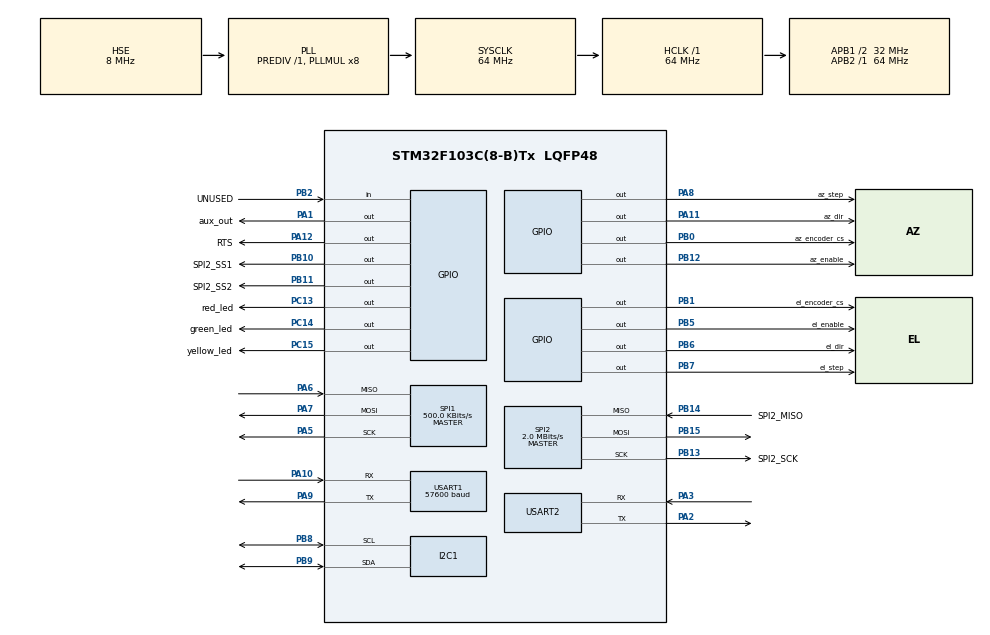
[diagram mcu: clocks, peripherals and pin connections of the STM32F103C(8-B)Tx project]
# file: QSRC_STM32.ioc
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Dma.Request0=USART2_RX
Dma.Request1=USART2_TX
Dma.Request2=USART1_RX
Dma.Request3=USART1_TX
Dma.USART1_RX.2.Direction=DMA_PERIPH_TO_MEMORY
Dma.USART1_RX.2.Instance=DMA1_Channel5
Dma.USART1_RX.2.MemDataAlignment=DMA_MDATAALIGN_BYTE
Dma.USART1_RX.2.MemInc=DMA_MINC_ENABLE
Dma.USART1_RX.2.Mode=DMA_NORMAL
Dma.USART1_RX.2.PeriphDataAlignment=DMA_PDATAALIGN_BYTE
Dma.USART1_RX.2.PeriphInc=DMA_PINC_DISABLE
Dma.USART1_RX.2.Priority=DMA_PRIORITY_MEDIUM
Dma.USART1_TX.3.Direction=DMA_MEMORY_TO_PERIPH
Dma.USART1_TX.3.Instance=DMA1_Channel4
Dma.USART1_TX.3.MemDataAlignment=DMA_MDATAALIGN_BYTE
Dma.USART1_TX.3.MemInc=DMA_MINC_ENABLE
Dma.USART1_TX.3.Mode=DMA_NORMAL
Dma.USART1_TX.3.PeriphDataAlignment=DMA_PDATAALIGN_BYTE
Dma.USART1_TX.3.PeriphInc=DMA_PINC_DISABLE
Dma.USART1_TX.3.Priority=DMA_PRIORITY_MEDIUM
Dma.USART2_RX.0.Direction=DMA_PERIPH_TO_MEMORY
Dma.USART2_RX.0.Instance=DMA1_Channel6
Dma.USART2_RX.0.MemDataAlignment=DMA_MDATAALIGN_BYTE
Dma.USART2_RX.0.MemInc=DMA_MINC_ENABLE
Dma.USART2_RX.0.Mode=DMA_NORMAL
Dma.USART2_RX.0.PeriphDataAlignment=DMA_PDATAALIGN_BYTE
Dma.USART2_RX.0.PeriphInc=DMA_PINC_DISABLE
Dma.USART2_RX.0.Priority=DMA_PRIORITY_LOW
Dma.USART2_TX.1.Direction=DMA_MEMORY_TO_PERIPH
Dma.USART2_TX.1.Instance=DMA1_Channel7
Dma.USART2_TX.1.MemDataAlignment=DMA_MDATAALIGN_BYTE
Dma.USART2_TX.1.MemInc=DMA_MINC_ENABLE
Dma.USART2_TX.1.Mode=DMA_NORMAL
Dma.USART2_TX.1.PeriphDataAlignment=DMA_PDATAALIGN_BYTE
Dma.USART2_TX.1.PeriphInc=DMA_PINC_DISABLE
Dma.USART2_TX.1.Priority=DMA_PRIORITY_LOW
Mcu.Family=STM32F1
Mcu.Name=STM32F103C(8-B)Tx
Mcu.Package=LQFP48
NVIC.DMA1_Channel4_IRQn=true\:0\:0\:false\:false\:true\:true\:true
NVIC.DMA1_Channel5_IRQn=true\:0\:0\:false\:false\:true\:true\:true
NVIC.DMA1_Channel6_IRQn=true\:0\:0\:false\:false\:true\:true\:true
NVIC.DMA1_Channel7_IRQn=true\:0\:0\:false\:false\:true\:true\:true
NVIC.I2C1_ER_IRQn=true\:0\:0\:false\:false\:true\:true\:true
NVIC.I2C1_EV_IRQn=true\:0\:0\:false\:false\:true\:true\:true
NVIC.PriorityGroup=NVIC_PRIORITYGROUP_4
NVIC.SPI1_IRQn=true\:0\:0\:false\:false\:true\:true\:true
NVIC.TIM2_IRQn=true\:7\:0\:true\:false\:true\:true\:true
NVIC.TIM3_IRQn=true\:7\:0\:true\:false\:true\:true\:true
NVIC.TIM4_IRQn=true\:0\:0\:false\:false\:true\:true\:true
NVIC.USART1_IRQn=true\:0\:0\:false\:false\:true\:true\:true
NVIC.USART2_IRQn=true\:0\:0\:false\:false\:true\:true\:true
PA1.GPIO_Label=aux_out
PA1.Signal=GPIO_Output
PA10.GPIO_PuPd=GPIO_PULLUP
PA10.Mode=Asynchronous
PA10.Signal=USART1_RX
PA11.GPIO_Label=az_dir
PA11.Signal=GPIO_Output
PA12.GPIO_Label=RTS
PA12.GPIO_Speed=GPIO_SPEED_FREQ_HIGH
PA12.Signal=GPIO_Output
PA13.Mode=JTAG_5_pins
PA13.Signal=SYS_JTMS-SWDIO
PA14.Mode=JTAG_5_pins
PA14.Signal=SYS_JTCK-SWCLK
PA15.Mode=JTAG_5_pins
PA15.Signal=SYS_JTDI
PA2.Mode=Asynchronous
PA2.Signal=USART2_TX
PA3.Mode=Asynchronous
PA3.Signal=USART2_RX
PA5.Mode=Full_Duplex_Master
PA5.Signal=SPI1_SCK
PA6.Mode=Full_Duplex_Master
PA6.Signal=SPI1_MISO
PA7.Mode=Full_Duplex_Master
PA7.Signal=SPI1_MOSI
PA8.GPIO_Label=az_step
PA8.Signal=GPIO_Output
PA9.Mode=Asynchronous
PA9.Signal=USART1_TX
PB0.GPIO_Label=az_encoder_cs
PB0.GPIO_Speed=GPIO_SPEED_FREQ_HIGH
PB0.PinState=GPIO_PIN_SET
PB0.Signal=GPIO_Output
PB1.GPIO_Label=el_encoder_cs
PB1.GPIO_Speed=GPIO_SPEED_FREQ_HIGH
PB1.PinState=GPIO_PIN_SET
PB1.Signal=GPIO_Output
PB10.GPIO_Label=SPI2_SS1
PB10.Signal=GPIO_Output
PB11.GPIO_Label=SPI2_SS2
PB11.Signal=GPIO_Output
PB12.GPIO_Label=az_enable
PB12.GPIO_Speed=GPIO_SPEED_FREQ_HIGH
PB12.PinState=GPIO_PIN_SET
PB12.Signal=GPIO_Output
PB13.GPIO_Label=SPI2_SCK
PB13.GPIO_Speed=GPIO_SPEED_FREQ_HIGH
PB13.Mode=Full_Duplex_Master
PB13.Signal=SPI2_SCK
PB14.GPIO_Label=SPI2_MISO
PB14.GPIO_Speed=GPIO_SPEED_FREQ_HIGH
PB14.Mode=Full_Duplex_Master
PB14.Signal=SPI2_MISO
PB15.Mode=Full_Duplex_Master
PB15.Signal=SPI2_MOSI
PB2.GPIO_Label=UNUSED
PB2.Signal=GPIO_Input
PB3.Mode=JTAG_5_pins
PB3.Signal=SYS_JTDO-TRACESWO
PB4.Mode=JTAG_5_pins
PB4.Signal=SYS_NJTRST
PB5.GPIO_Label=el_enable
PB5.GPIO_Speed=GPIO_SPEED_FREQ_HIGH
PB5.PinState=GPIO_PIN_SET
PB5.Signal=GPIO_Output
PB6.GPIO_Label=el_dir
PB6.GPIO_Speed=GPIO_SPEED_FREQ_HIGH
PB6.Signal=GPIO_Output
PB7.GPIO_Label=el_step
PB7.GPIO_Speed=GPIO_SPEED_FREQ_HIGH
PB7.Signal=GPIO_Output
PB8.Mode=I2C
PB8.Signal=I2C1_SCL
PB9.Mode=I2C
PB9.Signal=I2C1_SDA
PC13-TAMPER-RTC.GPIO_Label=red_led
PC13-TAMPER-RTC.GPIO_Speed=GPIO_SPEED_FREQ_LOW
PC13-TAMPER-RTC.PinState=GPIO_PIN_RESET
PC13-TAMPER-RTC.Signal=GPIO_Output
PC14-OSC32_IN.GPIO_Label=green_led
PC14-OSC32_IN.PinState=GPIO_PIN_RESET
PC14-OSC32_IN.Signal=GPIO_Output
PC15-OSC32_OUT.GPIO_Label=yellow_led
PC15-OSC32_OUT.PinState=GPIO_PIN_RESET
PC15-OSC32_OUT.Signal=GPIO_Output
PD0-OSC_IN.Mode=HSE-External-Oscillator
PD0-OSC_IN.Signal=RCC_OSC_IN
PD1-OSC_OUT.Mode=HSE-External-Oscillator
PD1-OSC_OUT.Signal=RCC_OSC_OUT
ProjectManager.HeapSize=0x200
ProjectManager.StackSize=0x400
ProjectManager.TargetToolchain=SW4STM32
RCC.AHBFreq_Value=64000000
RCC.APB1CLKDivider=RCC_HCLK_DIV2
RCC.APB1Freq_Value=32000000
RCC.APB1TimFreq_Value=64000000
RCC.APB2Freq_Value=64000000
RCC.APB2TimFreq_Value=64000000
RCC.HCLKFreq_Value=64000000
RCC.PLLMUL=RCC_PLL_MUL8
RCC.PLLSourceVirtual=RCC_PLLSOURCE_HSE
RCC.RTCClockSelection=RCC_RTCCLKSOURCE_HSE_DIV128
RCC.SYSCLKFreq_VALUE=64000000
RCC.SYSCLKSource=RCC_SYSCLKSOURCE_PLLCLK
RCC.USBFreq_Value=64000000
SPI1.BaudRatePrescaler=SPI_BAUDRATEPRESCALER_128
SPI1.CLKPhase=SPI_PHASE_2EDGE
SPI1.CLKPolarity=SPI_POLARITY_LOW
SPI1.CalculateBaudRate=500.0 KBits/s
SPI1.DataSize=SPI_DATASIZE_16BIT
SPI1.Direction=SPI_DIRECTION_2LINES
SPI1.Mode=SPI_MODE_MASTER
SPI1.VirtualType=VM_MASTER
SPI2.BaudRatePrescaler=SPI_BAUDRATEPRESCALER_16
SPI2.CalculateBaudRate=2.0 MBits/s
SPI2.Direction=SPI_DIRECTION_2LINES
SPI2.Mode=SPI_MODE_MASTER
SPI2.VirtualType=VM_MASTER
TIM2.CounterMode=TIM_COUNTERMODE_DOWN
TIM2.Prescaler=128
TIM3.Prescaler=128
TIM4.AutoReloadPreload=TIM_AUTORELOAD_PRELOAD_ENABLE
TIM4.Period=9
TIM4.Prescaler=6399
USART1.BaudRate=57600
USART1.VirtualMode=VM_ASYNC
USART1.WordLength=WORDLENGTH_8B
USART2.VirtualMode=VM_ASYNC
VP_RTC_VS_RTC_Activate.Mode=RTC_Enabled
VP_TIM2_VS_ClockSourceINT.Mode=Internal
VP_TIM3_VS_ClockSourceINT.Mode=Internal
VP_TIM4_VS_ClockSourceINT.Mode=Internal
board=QSRC_STM32

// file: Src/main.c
/* USER CODE BEGIN Header */
/**
  ******************************************************************************
  * @file           : main.c
  * @brief          : Main program body
  ******************************************************************************
  * @attention
  *
  * <h2><center>&copy; Copyright (c) 2020 STMicroelectronics.
  * All rights reserved.</center></h2>
  *
  * This software component is licensed by ST under BSD 3-Clause license,
  * the "License"; You may not use this file except in compliance with the
  * License. You may obtain a copy of the License at:
  *                        opensource.org/licenses/BSD-3-Clause
  *
  ******************************************************************************
  */
/* USER CODE END Header */

#include "main.h"
#include "dma.h"
#include "i2c.h"
#include "rtc.h"
#include "spi.h"
#include "tim.h"
#include "usart.h"
#include "gpio.h"

/* USER CODE BEGIN Includes */
#include "startup.h"
/* USER CODE END Includes */

/* USER CODE BEGIN PV */
/* Private variables ---------------------------------------------------------*/

/* USER CODE END PV */

void SystemClock_Config(void);
/* USER CODE BEGIN PFP */
/* Private function prototypes -----------------------------------------------*/

/* USER CODE END PFP */

int main(void)
{

  /* MCU Configuration--------------------------------------------------------*/

  /* Reset of all peripherals, Initializes the Flash interface and the Systick. */
  HAL_Init();

  /* Configure the system clock */
  SystemClock_Config();

  /* Initialize all configured peripherals */
  MX_GPIO_Init();
  MX_DMA_Init();
  MX_USART1_UART_Init();
  MX_USART2_UART_Init();
  MX_TIM2_Init();
  MX_TIM3_Init();
  MX_SPI1_Init();
  MX_I2C1_Init();
  MX_RTC_Init();
  MX_SPI2_Init();
  MX_TIM4_Init();

  /* Infinite loop */
  /* USER CODE BEGIN WHILE */
    startup();
  while (1)
  {
    /* USER CODE END WHILE */

    /* USER CODE BEGIN 3 */
//      HAL_GPIO_TogglePin(GPIOC, GPIO_PIN_13);
//      HAL_Delay(100);
  }
  /* USER CODE END 3 */
}

void SystemClock_Config(void)
{
  RCC_OscInitTypeDef RCC_OscInitStruct = {0};
  RCC_ClkInitTypeDef RCC_ClkInitStruct = {0};
  RCC_PeriphCLKInitTypeDef PeriphClkInit = {0};

  /** Initializes the CPU, AHB and APB busses clocks
  */
  RCC_OscInitStruct.OscillatorType = RCC_OSCILLATORTYPE_HSE;
  RCC_OscInitStruct.HSEState = RCC_HSE_ON;
  RCC_OscInitStruct.HSEPredivValue = RCC_HSE_PREDIV_DIV1;
  RCC_OscInitStruct.HSIState = RCC_HSI_ON;
  RCC_OscInitStruct.PLL.PLLState = RCC_PLL_ON;
  RCC_OscInitStruct.PLL.PLLSource = RCC_PLLSOURCE_HSE;
  RCC_OscInitStruct.PLL.PLLMUL = RCC_PLL_MUL8;
  if (HAL_RCC_OscConfig(&RCC_OscInitStruct) != HAL_OK)
  {
    Error_Handler();
  }
  /** Initializes the CPU, AHB and APB busses clocks
  */
  RCC_ClkInitStruct.ClockType = RCC_CLOCKTYPE_HCLK|RCC_CLOCKTYPE_SYSCLK
                              |RCC_CLOCKTYPE_PCLK1|RCC_CLOCKTYPE_PCLK2;
  RCC_ClkInitStruct.SYSCLKSource = RCC_SYSCLKSOURCE_PLLCLK;
  RCC_ClkInitStruct.AHBCLKDivider = RCC_SYSCLK_DIV1;
  RCC_ClkInitStruct.APB1CLKDivider = RCC_HCLK_DIV2;
  RCC_ClkInitStruct.APB2CLKDivider = RCC_HCLK_DIV1;

  if (HAL_RCC_ClockConfig(&RCC_ClkInitStruct, FLASH_LATENCY_2) != HAL_OK)
  {
    Error_Handler();
  }
  PeriphClkInit.PeriphClockSelection = RCC_PERIPHCLK_RTC;
  PeriphClkInit.RTCClockSelection = RCC_RTCCLKSOURCE_HSE_DIV128;
  if (HAL_RCCEx_PeriphCLKConfig(&PeriphClkInit) != HAL_OK)
  {
    Error_Handler();
  }
}

void Error_Handler(void)
{
  while(1)
  {
  }
}

/************************ (C) COPYRIGHT STMicroelectronics *****END OF FILE****/
